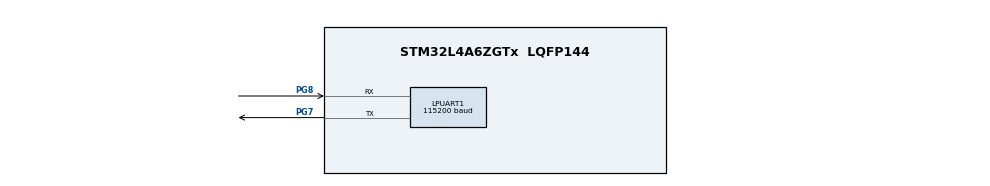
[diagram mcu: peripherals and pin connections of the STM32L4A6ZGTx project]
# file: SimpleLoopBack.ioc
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Dma.LPUART_RX.0.Direction=DMA_PERIPH_TO_MEMORY
Dma.LPUART_RX.0.Instance=DMA2_Channel7
Dma.LPUART_RX.0.MemDataAlignment=DMA_MDATAALIGN_BYTE
Dma.LPUART_RX.0.MemInc=DMA_MINC_ENABLE
Dma.LPUART_RX.0.Mode=DMA_CIRCULAR
Dma.LPUART_RX.0.PeriphDataAlignment=DMA_PDATAALIGN_BYTE
Dma.LPUART_RX.0.PeriphInc=DMA_PINC_DISABLE
Dma.LPUART_RX.0.Priority=DMA_PRIORITY_LOW
Dma.Request0=LPUART_RX
LPUART1.BaudRate=115200
LPUART1.WordLength=UART_WORDLENGTH_8B
Mcu.Family=STM32L4
Mcu.Name=STM32L4A6ZGTx
Mcu.Package=LQFP144
NVIC.DMA2_Channel7_IRQn=true\:0\:0\:false\:false\:true\:false\:true
NVIC.LPUART1_IRQn=true\:0\:0\:false\:false\:true\:true\:true
NVIC.PriorityGroup=NVIC_PRIORITYGROUP_4
PG7.Mode=Asynchronous
PG7.Signal=LPUART1_TX
PG8.Mode=Asynchronous
PG8.Signal=LPUART1_RX
ProjectManager.HeapSize=0x200
ProjectManager.StackSize=0x400
ProjectManager.TargetToolchain=EWARM V8.32
RCC.HSE_VALUE=8000000
RCC.HSI48_VALUE=48000000
RCC.HSI_VALUE=16000000
RCC.LSE_VALUE=32768
RCC.MSI_VALUE=4000000
RCC.VCOOutputFreq_Value=32000000
board=custom

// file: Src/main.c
/* USER CODE BEGIN Header */
/**
  ******************************************************************************
  * @file           : main.c
  * @brief          : Main program body
  ******************************************************************************
  * @attention
  *
  * <h2><center>&copy; Copyright (c) 2019 STMicroelectronics.
  * All rights reserved.</center></h2>
  *
  * This software component is licensed by ST under BSD 3-Clause license,
  * the "License"; You may not use this file except in compliance with the
  * License. You may obtain a copy of the License at:
  *                        opensource.org/licenses/BSD-3-Clause
  *
  ******************************************************************************
  */
/* USER CODE END Header */

#include "main.h"
#include "stdio.h"

UART_HandleTypeDef hlpuart1;
DMA_HandleTypeDef hdma_lpuart_rx;

void SystemClock_Config(void);
static void MX_GPIO_Init(void);
static void MX_DMA_Init(void);
static void MX_LPUART1_UART_Init(void);

/* USER CODE BEGIN 0 */
uint8_t myTxData[16] = "Hello from STM!";
uint8_t myRxData[32];
int c = 0;

/* USER CODE END 0 */

int main(void)
{

  /* MCU Configuration--------------------------------------------------------*/

  /* Reset of all peripherals, Initializes the Flash interface and the Systick. */
  HAL_Init();

  /* Configure the system clock */
  SystemClock_Config();

  /* Initialize all configured peripherals */
  MX_GPIO_Init();
  MX_DMA_Init();
  MX_LPUART1_UART_Init();
  /* Infinite loop */
  while (1)
  {
    HAL_UART_Receive_IT(&hlpuart1 , myRxData , 19);
    HAL_Delay(1000);
    HAL_UART_Transmit_IT(&hlpuart1 , myTxData , 15);
  }
}

void SystemClock_Config(void)
{
  RCC_OscInitTypeDef RCC_OscInitStruct = {0};
  RCC_ClkInitTypeDef RCC_ClkInitStruct = {0};
  RCC_PeriphCLKInitTypeDef PeriphClkInit = {0};

  /** Initializes the CPU, AHB and APB busses clocks
  */
  RCC_OscInitStruct.OscillatorType = RCC_OSCILLATORTYPE_MSI;
  RCC_OscInitStruct.MSIState = RCC_MSI_ON;
  RCC_OscInitStruct.MSICalibrationValue = 0;
  RCC_OscInitStruct.MSIClockRange = RCC_MSIRANGE_6;
  RCC_OscInitStruct.PLL.PLLState = RCC_PLL_NONE;
  if (HAL_RCC_OscConfig(&RCC_OscInitStruct) != HAL_OK)
  {
    Error_Handler();
  }
  /** Initializes the CPU, AHB and APB busses clocks
  */
  RCC_ClkInitStruct.ClockType = RCC_CLOCKTYPE_HCLK|RCC_CLOCKTYPE_SYSCLK
                              |RCC_CLOCKTYPE_PCLK1|RCC_CLOCKTYPE_PCLK2;
  RCC_ClkInitStruct.SYSCLKSource = RCC_SYSCLKSOURCE_MSI;
  RCC_ClkInitStruct.AHBCLKDivider = RCC_SYSCLK_DIV1;
  RCC_ClkInitStruct.APB1CLKDivider = RCC_HCLK_DIV1;
  RCC_ClkInitStruct.APB2CLKDivider = RCC_HCLK_DIV1;

  if (HAL_RCC_ClockConfig(&RCC_ClkInitStruct, FLASH_LATENCY_0) != HAL_OK)
  {
    Error_Handler();
  }
  PeriphClkInit.PeriphClockSelection = RCC_PERIPHCLK_LPUART1;
  PeriphClkInit.Lpuart1ClockSelection = RCC_LPUART1CLKSOURCE_PCLK1;
  if (HAL_RCCEx_PeriphCLKConfig(&PeriphClkInit) != HAL_OK)
  {
    Error_Handler();
  }
  /** Configure the main internal regulator output voltage
  */
  if (HAL_PWREx_ControlVoltageScaling(PWR_REGULATOR_VOLTAGE_SCALE1) != HAL_OK)
  {
    Error_Handler();
  }
}

static void MX_LPUART1_UART_Init(void)
{

  hlpuart1.Instance = LPUART1;
  hlpuart1.Init.BaudRate = 9600;
  hlpuart1.Init.WordLength = UART_WORDLENGTH_8B;
  hlpuart1.Init.StopBits = UART_STOPBITS_1;
  hlpuart1.Init.Parity = UART_PARITY_NONE;
  hlpuart1.Init.Mode = UART_MODE_TX_RX;
  hlpuart1.Init.HwFlowCtl = UART_HWCONTROL_NONE;
  hlpuart1.Init.OneBitSampling = UART_ONE_BIT_SAMPLE_DISABLE;
  hlpuart1.AdvancedInit.AdvFeatureInit = UART_ADVFEATURE_NO_INIT;
  if (HAL_UART_Init(&hlpuart1) != HAL_OK)
  {
    Error_Handler();
  }

}

static void MX_DMA_Init(void)
{

  /* DMA controller clock enable */
  __HAL_RCC_DMA2_CLK_ENABLE();

  /* DMA interrupt init */
  /* DMA2_Channel7_IRQn interrupt configuration */
  HAL_NVIC_SetPriority(DMA2_Channel7_IRQn, 0, 0);
  HAL_NVIC_EnableIRQ(DMA2_Channel7_IRQn);

}

static void MX_GPIO_Init(void)
{

  /* GPIO Ports Clock Enable */
  __HAL_RCC_GPIOG_CLK_ENABLE();
  HAL_PWREx_EnableVddIO2();

}

/* USER CODE BEGIN 4 */
void HAL_UART_TxCpltCallback(UART_HandleTypeDef *huart)
{
  c++;
  printf("Ping %d !\n", c);
}
/* USER CODE END 4 */

void Error_Handler(void)
{
}

/************************ (C) COPYRIGHT STMicroelectronics *****END OF FILE****/
